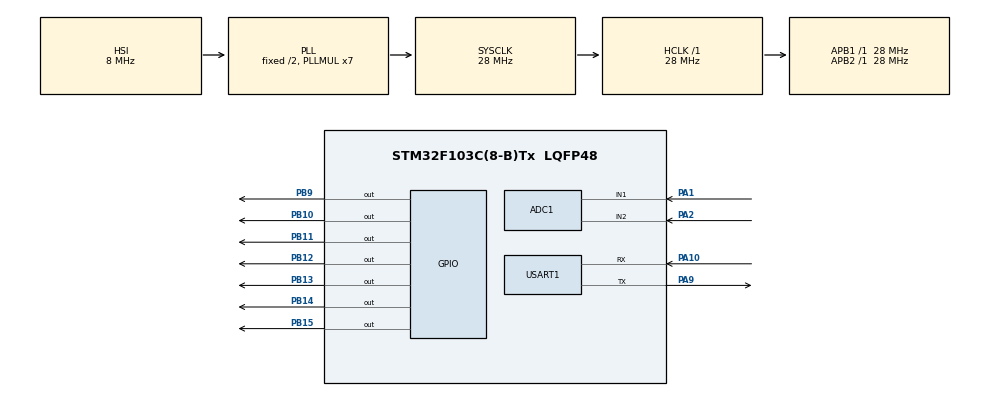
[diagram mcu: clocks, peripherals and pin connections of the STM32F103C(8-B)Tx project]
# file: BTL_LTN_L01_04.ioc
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ADC1.Channel-5\#ChannelRegularConversion=ADC_CHANNEL_1
ADC1.Channel-6\#ChannelRegularConversion=ADC_CHANNEL_2
ADC1.ContinuousConvMode=ENABLE
ADC1.NbrOfConversion=2
ADC1.NbrOfConversionFlag=1
ADC1.Rank-5\#ChannelRegularConversion=1
ADC1.Rank-6\#ChannelRegularConversion=2
ADC1.SamplingTime-5\#ChannelRegularConversion=ADC_SAMPLETIME_1CYCLE_5
ADC1.SamplingTime-6\#ChannelRegularConversion=ADC_SAMPLETIME_1CYCLE_5
ADC1.master=1
Dma.ADC1.0.Direction=DMA_PERIPH_TO_MEMORY
Dma.ADC1.0.Instance=DMA1_Channel1
Dma.ADC1.0.MemDataAlignment=DMA_MDATAALIGN_WORD
Dma.ADC1.0.MemInc=DMA_MINC_ENABLE
Dma.ADC1.0.Mode=DMA_CIRCULAR
Dma.ADC1.0.PeriphDataAlignment=DMA_PDATAALIGN_WORD
Dma.ADC1.0.PeriphInc=DMA_PINC_DISABLE
Dma.ADC1.0.Priority=DMA_PRIORITY_LOW
Dma.Request0=ADC1
Mcu.Family=STM32F1
Mcu.Name=STM32F103C(8-B)Tx
Mcu.Package=LQFP48
NVIC.DMA1_Channel1_IRQn=true\:0\:0\:false\:false\:true\:false\:true\:true
NVIC.PriorityGroup=NVIC_PRIORITYGROUP_4
PA1.Signal=ADCx_IN1
PA10.Mode=Asynchronous
PA10.Signal=USART1_RX
PA13.Mode=Serial_Wire
PA13.Signal=SYS_JTMS-SWDIO
PA14.Mode=Serial_Wire
PA14.Signal=SYS_JTCK-SWCLK
PA2.Signal=ADCx_IN2
PA9.Mode=Asynchronous
PA9.Signal=USART1_TX
PB10.Signal=GPIO_Output
PB11.Signal=GPIO_Output
PB12.Signal=GPIO_Output
PB13.Signal=GPIO_Output
PB14.Signal=GPIO_Output
PB15.Signal=GPIO_Output
PB9.Signal=GPIO_Output
PD0-OSC_IN.Mode=HSE-External-Oscillator
PD0-OSC_IN.Signal=RCC_OSC_IN
PD1-OSC_OUT.Mode=HSE-External-Oscillator
PD1-OSC_OUT.Signal=RCC_OSC_OUT
ProjectManager.HeapSize=0x200
ProjectManager.StackSize=0x400
ProjectManager.TargetToolchain=STM32CubeIDE
RCC.AHBFreq_Value=28000000
RCC.APB1Freq_Value=28000000
RCC.APB1TimFreq_Value=28000000
RCC.APB2Freq_Value=28000000
RCC.APB2TimFreq_Value=28000000
RCC.HCLKFreq_Value=28000000
RCC.PLLMUL=RCC_PLL_MUL7
RCC.SYSCLKFreq_VALUE=28000000
RCC.SYSCLKSource=RCC_SYSCLKSOURCE_PLLCLK
RCC.USBFreq_Value=28000000
SH.ADCx_IN1.0=ADC1_IN1,IN1
SH.ADCx_IN2.0=ADC1_IN2,IN2
USART1.VirtualMode=VM_ASYNC
board=custom

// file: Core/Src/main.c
/* USER CODE BEGIN Header */
/**
  ******************************************************************************
  * @file           : main.c
  * @brief          : Main program body
  ******************************************************************************
  * @attention
  *
  * Copyright (c) 2024 STMicroelectronics.
  * All rights reserved.
  *
  * This software is licensed under terms that can be found in the LICENSE file
  * in the root directory of this software component.
  * If no LICENSE file comes with this software, it is provided AS-IS.
  *
  ******************************************************************************
  */
/* USER CODE END Header */
#include "main.h"

/* USER CODE BEGIN Includes */
#include "LM35.h"
#include "LM393.h"
#include "LCD.h"
/* USER CODE END Includes */

/* USER CODE BEGIN PD */
void Display_Sensor_Task();
void Control_Pump_Task(int state);

/* USER CODE END PD */

ADC_HandleTypeDef hadc1;
DMA_HandleTypeDef hdma_adc1;

UART_HandleTypeDef huart1;

/* USER CODE BEGIN PV */
//  uint16_t a[2];
	float temperature ;
	float humidity ;
/* USER CODE END PV */

void SystemClock_Config(void);
static void MX_GPIO_Init(void);
static void MX_DMA_Init(void);
static void MX_USART1_UART_Init(void);
static void MX_ADC1_Init(void);

int main(void)
{
  /* USER CODE BEGIN 1 */
//	float temperature = 0;
//	float humidity = 0;
  /* USER CODE END 1 */

  /* MCU Configuration--------------------------------------------------------*/

  /* Reset of all peripherals, Initializes the Flash interface and the Systick. */
  HAL_Init();

  /* Configure the system clock */
  SystemClock_Config();

  /* Initialize all configured peripherals */
  MX_GPIO_Init();
  MX_DMA_Init();
  MX_USART1_UART_Init();
  MX_ADC1_Init();
  /* USER CODE BEGIN 2 */
  LM35_Init(&hadc1);
  LM393_Init(&hadc1);
  lcd_init();
  lcd_clear();
  lcd_cursor(1, 0);
  lcd_string("Hello World!");
  read_sensor();
  /* USER CODE END 2 */

  /* Infinite loop */
  while (1)
  {
	humidity = get_Humidity();
	temperature = get_Temperature();
    /* USER CODE BEGIN 3 */
//	 HAL_ADC_Start_DMA(&hadc1,(uint16_t*)a,2);
//	 temperature = LM35_ReadTemperature();
//	 humidity = LM393_ReadHumidity();
//	 HAL_Delay(500);
  }
  /* USER CODE END 3 */
}

void SystemClock_Config(void)
{
  RCC_OscInitTypeDef RCC_OscInitStruct = {0};
  RCC_ClkInitTypeDef RCC_ClkInitStruct = {0};
  RCC_PeriphCLKInitTypeDef PeriphClkInit = {0};

  /** Initializes the RCC Oscillators according to the specified parameters
  * in the RCC_OscInitTypeDef structure.
  */
  RCC_OscInitStruct.OscillatorType = RCC_OSCILLATORTYPE_HSI;
  RCC_OscInitStruct.HSIState = RCC_HSI_ON;
  RCC_OscInitStruct.HSICalibrationValue = RCC_HSICALIBRATION_DEFAULT;
  RCC_OscInitStruct.PLL.PLLState = RCC_PLL_ON;
  RCC_OscInitStruct.PLL.PLLSource = RCC_PLLSOURCE_HSI_DIV2;
  RCC_OscInitStruct.PLL.PLLMUL = RCC_PLL_MUL7;
  if (HAL_RCC_OscConfig(&RCC_OscInitStruct) != HAL_OK)
  {
    Error_Handler();
  }

  /** Initializes the CPU, AHB and APB buses clocks
  */
  RCC_ClkInitStruct.ClockType = RCC_CLOCKTYPE_HCLK|RCC_CLOCKTYPE_SYSCLK
                              |RCC_CLOCKTYPE_PCLK1|RCC_CLOCKTYPE_PCLK2;
  RCC_ClkInitStruct.SYSCLKSource = RCC_SYSCLKSOURCE_PLLCLK;
  RCC_ClkInitStruct.AHBCLKDivider = RCC_SYSCLK_DIV1;
  RCC_ClkInitStruct.APB1CLKDivider = RCC_HCLK_DIV1;
  RCC_ClkInitStruct.APB2CLKDivider = RCC_HCLK_DIV1;

  if (HAL_RCC_ClockConfig(&RCC_ClkInitStruct, FLASH_LATENCY_1) != HAL_OK)
  {
    Error_Handler();
  }
  PeriphClkInit.PeriphClockSelection = RCC_PERIPHCLK_ADC;
  PeriphClkInit.AdcClockSelection = RCC_ADCPCLK2_DIV2;
  if (HAL_RCCEx_PeriphCLKConfig(&PeriphClkInit) != HAL_OK)
  {
    Error_Handler();
  }
}

static void MX_ADC1_Init(void)
{

  ADC_ChannelConfTypeDef sConfig = {0};

  /** Common config
  */
  hadc1.Instance = ADC1;
  hadc1.Init.ScanConvMode = ADC_SCAN_ENABLE;
  hadc1.Init.ContinuousConvMode = ENABLE;
  hadc1.Init.DiscontinuousConvMode = DISABLE;
  hadc1.Init.ExternalTrigConv = ADC_SOFTWARE_START;
  hadc1.Init.DataAlign = ADC_DATAALIGN_RIGHT;
  hadc1.Init.NbrOfConversion = 2;
  if (HAL_ADC_Init(&hadc1) != HAL_OK)
  {
    Error_Handler();
  }

  /** Configure Regular Channel
  */
  sConfig.Channel = ADC_CHANNEL_1;
  sConfig.Rank = ADC_REGULAR_RANK_1;
  sConfig.SamplingTime = ADC_SAMPLETIME_1CYCLE_5;
  if (HAL_ADC_ConfigChannel(&hadc1, &sConfig) != HAL_OK)
  {
    Error_Handler();
  }

  /** Configure Regular Channel
  */
  sConfig.Channel = ADC_CHANNEL_2;
  sConfig.Rank = ADC_REGULAR_RANK_2;
  if (HAL_ADC_ConfigChannel(&hadc1, &sConfig) != HAL_OK)
  {
    Error_Handler();
  }

}

static void MX_USART1_UART_Init(void)
{

  huart1.Instance = USART1;
  huart1.Init.BaudRate = 115200;
  huart1.Init.WordLength = UART_WORDLENGTH_8B;
  huart1.Init.StopBits = UART_STOPBITS_1;
  huart1.Init.Parity = UART_PARITY_NONE;
  huart1.Init.Mode = UART_MODE_TX_RX;
  huart1.Init.HwFlowCtl = UART_HWCONTROL_NONE;
  huart1.Init.OverSampling = UART_OVERSAMPLING_16;
  if (HAL_UART_Init(&huart1) != HAL_OK)
  {
    Error_Handler();
  }

}

static void MX_DMA_Init(void)
{

  /* DMA controller clock enable */
  __HAL_RCC_DMA1_CLK_ENABLE();

  /* DMA interrupt init */
  /* DMA1_Channel1_IRQn interrupt configuration */
  HAL_NVIC_SetPriority(DMA1_Channel1_IRQn, 0, 0);
  HAL_NVIC_EnableIRQ(DMA1_Channel1_IRQn);

}

static void MX_GPIO_Init(void)
{
  GPIO_InitTypeDef GPIO_InitStruct = {0};

  /* GPIO Ports Clock Enable */
  __HAL_RCC_GPIOD_CLK_ENABLE();
  __HAL_RCC_GPIOA_CLK_ENABLE();
  __HAL_RCC_GPIOB_CLK_ENABLE();

  /*Configure GPIO pin Output Level */
  HAL_GPIO_WritePin(GPIOB, GPIO_PIN_10|GPIO_PIN_11|GPIO_PIN_12|GPIO_PIN_13
                          |GPIO_PIN_14|GPIO_PIN_15|GPIO_PIN_9, GPIO_PIN_RESET);

  /*Configure GPIO pins : PB10 PB11 PB12 PB13
                           PB14 PB15 PB9 */
  GPIO_InitStruct.Pin = GPIO_PIN_10|GPIO_PIN_11|GPIO_PIN_12|GPIO_PIN_13
                          |GPIO_PIN_14|GPIO_PIN_15|GPIO_PIN_9;
  GPIO_InitStruct.Mode = GPIO_MODE_OUTPUT_PP;
  GPIO_InitStruct.Pull = GPIO_NOPULL;
  GPIO_InitStruct.Speed = GPIO_SPEED_FREQ_LOW;
  HAL_GPIO_Init(GPIOB, &GPIO_InitStruct);

}

void Error_Handler(void)
{
  __disable_irq();
  while (1)
  {
  }
}
